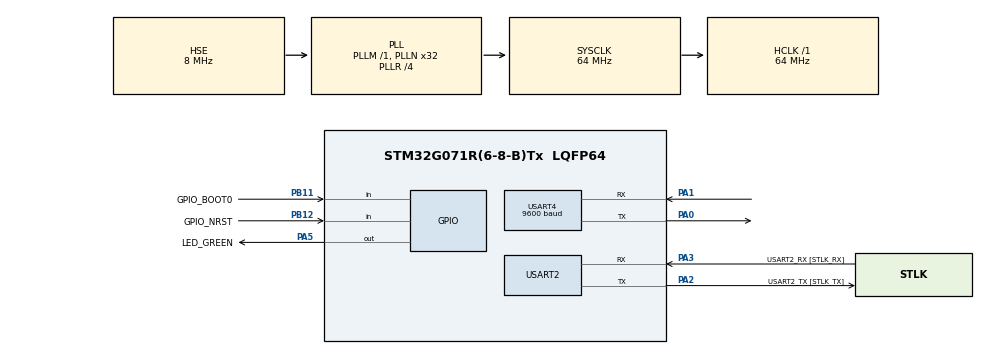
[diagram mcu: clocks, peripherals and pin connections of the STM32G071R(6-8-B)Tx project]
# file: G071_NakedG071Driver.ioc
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Dma.Request0=USART4_TX
Dma.Request1=USART4_RX
Dma.Request2=USART2_RX
Dma.Request3=USART2_TX
Dma.USART2_RX.2.Direction=DMA_PERIPH_TO_MEMORY
Dma.USART2_RX.2.EventEnable=DISABLE
Dma.USART2_RX.2.Instance=DMA1_Channel3
Dma.USART2_RX.2.MemDataAlignment=DMA_MDATAALIGN_BYTE
Dma.USART2_RX.2.MemInc=DMA_MINC_ENABLE
Dma.USART2_RX.2.Mode=DMA_NORMAL
Dma.USART2_RX.2.PeriphDataAlignment=DMA_PDATAALIGN_BYTE
Dma.USART2_RX.2.PeriphInc=DMA_PINC_DISABLE
Dma.USART2_RX.2.Polarity=HAL_DMAMUX_REQ_GEN_RISING
Dma.USART2_RX.2.Priority=DMA_PRIORITY_LOW
Dma.USART2_RX.2.RequestNumber=1
Dma.USART2_RX.2.SignalID=NONE
Dma.USART2_RX.2.SyncEnable=DISABLE
Dma.USART2_RX.2.SyncPolarity=HAL_DMAMUX_SYNC_NO_EVENT
Dma.USART2_RX.2.SyncRequestNumber=1
Dma.USART2_RX.2.SyncSignalID=NONE
Dma.USART2_TX.3.Direction=DMA_MEMORY_TO_PERIPH
Dma.USART2_TX.3.EventEnable=DISABLE
Dma.USART2_TX.3.Instance=DMA1_Channel4
Dma.USART2_TX.3.MemDataAlignment=DMA_MDATAALIGN_BYTE
Dma.USART2_TX.3.MemInc=DMA_MINC_ENABLE
Dma.USART2_TX.3.Mode=DMA_NORMAL
Dma.USART2_TX.3.PeriphDataAlignment=DMA_PDATAALIGN_BYTE
Dma.USART2_TX.3.PeriphInc=DMA_PINC_DISABLE
Dma.USART2_TX.3.Polarity=HAL_DMAMUX_REQ_GEN_RISING
Dma.USART2_TX.3.Priority=DMA_PRIORITY_LOW
Dma.USART2_TX.3.RequestNumber=1
Dma.USART2_TX.3.SignalID=NONE
Dma.USART2_TX.3.SyncEnable=DISABLE
Dma.USART2_TX.3.SyncPolarity=HAL_DMAMUX_SYNC_NO_EVENT
Dma.USART2_TX.3.SyncRequestNumber=1
Dma.USART2_TX.3.SyncSignalID=NONE
Dma.USART4_RX.1.Direction=DMA_PERIPH_TO_MEMORY
Dma.USART4_RX.1.EventEnable=DISABLE
Dma.USART4_RX.1.Instance=DMA1_Channel2
Dma.USART4_RX.1.MemDataAlignment=DMA_MDATAALIGN_BYTE
Dma.USART4_RX.1.MemInc=DMA_MINC_ENABLE
Dma.USART4_RX.1.Mode=DMA_NORMAL
Dma.USART4_RX.1.PeriphDataAlignment=DMA_PDATAALIGN_BYTE
Dma.USART4_RX.1.PeriphInc=DMA_PINC_DISABLE
Dma.USART4_RX.1.Polarity=HAL_DMAMUX_REQ_GEN_RISING
Dma.USART4_RX.1.Priority=DMA_PRIORITY_LOW
Dma.USART4_RX.1.RequestNumber=1
Dma.USART4_RX.1.SignalID=NONE
Dma.USART4_RX.1.SyncEnable=DISABLE
Dma.USART4_RX.1.SyncPolarity=HAL_DMAMUX_SYNC_NO_EVENT
Dma.USART4_RX.1.SyncRequestNumber=1
Dma.USART4_RX.1.SyncSignalID=NONE
Dma.USART4_TX.0.Direction=DMA_MEMORY_TO_PERIPH
Dma.USART4_TX.0.EventEnable=DISABLE
Dma.USART4_TX.0.Instance=DMA1_Channel1
Dma.USART4_TX.0.MemDataAlignment=DMA_MDATAALIGN_BYTE
Dma.USART4_TX.0.MemInc=DMA_MINC_ENABLE
Dma.USART4_TX.0.Mode=DMA_NORMAL
Dma.USART4_TX.0.PeriphDataAlignment=DMA_PDATAALIGN_BYTE
Dma.USART4_TX.0.PeriphInc=DMA_PINC_DISABLE
Dma.USART4_TX.0.Polarity=HAL_DMAMUX_REQ_GEN_RISING
Dma.USART4_TX.0.Priority=DMA_PRIORITY_LOW
Dma.USART4_TX.0.RequestNumber=1
Dma.USART4_TX.0.SignalID=NONE
Dma.USART4_TX.0.SyncEnable=DISABLE
Dma.USART4_TX.0.SyncPolarity=HAL_DMAMUX_SYNC_NO_EVENT
Dma.USART4_TX.0.SyncRequestNumber=1
Dma.USART4_TX.0.SyncSignalID=NONE
Mcu.Family=STM32G0
Mcu.Name=STM32G071R(6-8-B)Tx
Mcu.Package=LQFP64
NVIC.DMA1_Ch4_7_DMAMUX1_OVR_IRQn=true\:0\:0\:false\:false\:true\:false\:true
NVIC.DMA1_Channel1_IRQn=true\:0\:0\:false\:false\:true\:false\:true
NVIC.DMA1_Channel2_3_IRQn=true\:0\:0\:false\:false\:true\:false\:true
NVIC.USART2_IRQn=true\:0\:0\:false\:false\:true\:true\:true
NVIC.USART3_4_LPUART1_IRQn=true\:0\:0\:false\:false\:true\:true\:true
PA0.GPIO_PuPd=GPIO_NOPULL
PA0.GPIO_Speed=GPIO_SPEED_FREQ_HIGH
PA0.Mode=Asynchronous
PA0.Signal=USART4_TX
PA1.GPIO_PuPd=GPIO_NOPULL
PA1.GPIO_Speed=GPIO_SPEED_FREQ_HIGH
PA1.Mode=Asynchronous
PA1.Signal=USART4_RX
PA13.GPIO_Label=TMS
PA13.Mode=Serial_Wire
PA13.Signal=SYS_SWDIO
PA14-BOOT0.GPIO_Label=TCK
PA14-BOOT0.Mode=Serial_Wire
PA14-BOOT0.Signal=SYS_SWCLK
PA2.GPIO_Label=USART2_TX [STLK_TX]
PA2.GPIO_PuPd=GPIO_PULLUP
PA2.GPIO_Speed=GPIO_SPEED_FREQ_LOW
PA2.Mode=Asynchronous
PA2.Signal=USART2_TX
PA3.GPIO_Label=USART2_RX [STLK_RX]
PA3.GPIO_PuPd=GPIO_PULLUP
PA3.Mode=Asynchronous
PA3.Signal=USART2_RX
PA5.GPIO_Label=LED_GREEN
PA5.GPIO_Speed=GPIO_SPEED_FREQ_HIGH
PA5.Signal=GPIO_Output
PB11.GPIO_Label=GPIO_BOOT0
PB11.Signal=GPIO_Input
PB12.GPIO_Label=GPIO_NRST
PB12.Signal=GPIO_Input
PC13.Mode=SYS_WakeUp1
PC13.Signal=SYS_WKUP2
PC14-OSC32_IN\ (PC14).Mode=LSE-External-Oscillator
PC14-OSC32_IN\ (PC14).Signal=RCC_OSC32_IN
PC15-OSC32_OUT\ (PC15).Mode=LSE-External-Oscillator
PC15-OSC32_OUT\ (PC15).Signal=RCC_OSC32_OUT
PF0-OSC_IN\ (PF0).GPIO_Label=MCO
PF0-OSC_IN\ (PF0).Mode=HSE-External-Clock-Source
PF0-OSC_IN\ (PF0).Signal=RCC_OSC_IN
ProjectManager.HeapSize=0x200
ProjectManager.StackSize=0x400
ProjectManager.TargetToolchain=STM32CubeIDE
RCC.ADCFreq_Value=64000000
RCC.AHBFreq_Value=64000000
RCC.CortexFreq_Value=64000000
RCC.EXTERNAL_CLOCK_VALUE=12288000
RCC.HCLKFreq_Value=64000000
RCC.HSE_VALUE=8000000
RCC.HSI_VALUE=16000000
RCC.PLLN=32
RCC.PLLR=RCC_PLLR_DIV4
RCC.PLLSourceVirtual=RCC_PLLSOURCE_HSE
RCC.SYSCLKFreq_VALUE=64000000
RCC.SYSCLKSource=RCC_SYSCLKSOURCE_PLLCLK
RCC.VCOOutputFreq_Value=256000000
TIM14.Period=7
TIM14.Prescaler=0
TIM3.Period=65535
TIM3.Prescaler=63999
USART2.VirtualMode-Asynchronous=VM_ASYNC
USART4.BaudRate=9600
USART4.Parity=PARITY_EVEN
USART4.VirtualMode-Asynchronous=VM_ASYNC
USART4.WordLength=WORDLENGTH_9B
VP_SYS_VS_DBSignals.Mode=DisableDeadBatterySignals
VP_TIM14_VS_ClockSourceINT.Mode=Enable_Timer
VP_TIM3_VS_ClockSourceINT.Mode=Internal
board=NUCLEO-G071RB

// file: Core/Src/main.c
/* USER CODE BEGIN Header */
/**
  ******************************************************************************
  * @file           : main.c
  * @brief          : Main program body
  ******************************************************************************
  * @attention
  *
  * <h2><center>&copy; Copyright (c) 2020 STMicroelectronics.
  * All rights reserved.</center></h2>
  *
  * This software component is licensed by ST under BSD 3-Clause license,
  * the "License"; You may not use this file except in compliance with the
  * License. You may obtain a copy of the License at:
  *                        opensource.org/licenses/BSD-3-Clause
  *
  ******************************************************************************
  */
/* USER CODE END Header */
#include "main.h"

TIM_HandleTypeDef htim3;
TIM_HandleTypeDef htim14;

UART_HandleTypeDef huart2;
UART_HandleTypeDef huart4;
DMA_HandleTypeDef hdma_usart2_rx;
DMA_HandleTypeDef hdma_usart2_tx;
DMA_HandleTypeDef hdma_usart4_tx;
DMA_HandleTypeDef hdma_usart4_rx;

/* USER CODE BEGIN PV */
uint8_t pc_rx_buff[10];
uint8_t pc_tx_buff[256];

/* USER CODE END PV */

void SystemClock_Config(void);
static void MX_GPIO_Init(void);
static void MX_DMA_Init(void);
static void MX_USART2_UART_Init(void);
static void MX_TIM14_Init(void);
static void MX_USART4_UART_Init(void);
static void MX_TIM3_Init(void);

int main(void)
{

  /* MCU Configuration--------------------------------------------------------*/

  /* Reset of all peripherals, Initializes the Flash interface and the Systick. */
  HAL_Init();

  /* Configure the system clock */
  SystemClock_Config();

  /* USER CODE BEGIN SysInit */
#if 0
  MX_GPIO_Init();
  MX_USART2_UART_Init();
  MX_TIM14_Init();
  MX_USART4_UART_Init();
  MX_DMA_Init();
#endif

#if 1
  /* USER CODE END SysInit */

  /* Initialize all configured peripherals */
  MX_GPIO_Init();
  MX_DMA_Init();
  MX_USART2_UART_Init();
  MX_TIM14_Init();
  MX_USART4_UART_Init();
  MX_TIM3_Init();
  /* USER CODE BEGIN 2 */
#endif

	HAL_UART_Receive_DMA(&huart2, pc_rx_buff, 1);

	//HAL_TIM_PWM_Start(&htim14, TIM_CHANNEL_1);

  /* USER CODE END 2 */

  /* Infinite loop */
  /* USER CODE BEGIN WHILE */
  while (1)
  {
	 // HAL_UART_Transmit_DMA(&huart2, pc_tx_buff, len);
	 // HAL_Delay(10);
    /* USER CODE END WHILE */

  }
}

void SystemClock_Config(void)
{
  RCC_OscInitTypeDef RCC_OscInitStruct = {0};
  RCC_ClkInitTypeDef RCC_ClkInitStruct = {0};
  RCC_PeriphCLKInitTypeDef PeriphClkInit = {0};

  /** Configure the main internal regulator output voltage
  */
  HAL_PWREx_ControlVoltageScaling(PWR_REGULATOR_VOLTAGE_SCALE1);
  /** Initializes the RCC Oscillators according to the specified parameters
  * in the RCC_OscInitTypeDef structure.
  */
  RCC_OscInitStruct.OscillatorType = RCC_OSCILLATORTYPE_HSE;
  RCC_OscInitStruct.HSEState = RCC_HSE_BYPASS;
  RCC_OscInitStruct.PLL.PLLState = RCC_PLL_ON;
  RCC_OscInitStruct.PLL.PLLSource = RCC_PLLSOURCE_HSE;
  RCC_OscInitStruct.PLL.PLLM = RCC_PLLM_DIV1;
  RCC_OscInitStruct.PLL.PLLN = 32;
  RCC_OscInitStruct.PLL.PLLP = RCC_PLLP_DIV2;
  RCC_OscInitStruct.PLL.PLLQ = RCC_PLLQ_DIV2;
  RCC_OscInitStruct.PLL.PLLR = RCC_PLLR_DIV4;
  if (HAL_RCC_OscConfig(&RCC_OscInitStruct) != HAL_OK)
  {
    Error_Handler();
  }
  /** Initializes the CPU, AHB and APB buses clocks
  */
  RCC_ClkInitStruct.ClockType = RCC_CLOCKTYPE_HCLK|RCC_CLOCKTYPE_SYSCLK
                              |RCC_CLOCKTYPE_PCLK1;
  RCC_ClkInitStruct.SYSCLKSource = RCC_SYSCLKSOURCE_PLLCLK;
  RCC_ClkInitStruct.AHBCLKDivider = RCC_SYSCLK_DIV1;
  RCC_ClkInitStruct.APB1CLKDivider = RCC_HCLK_DIV1;

  if (HAL_RCC_ClockConfig(&RCC_ClkInitStruct, FLASH_LATENCY_2) != HAL_OK)
  {
    Error_Handler();
  }
  /** Initializes the peripherals clocks
  */
  PeriphClkInit.PeriphClockSelection = RCC_PERIPHCLK_USART2;
  PeriphClkInit.Usart2ClockSelection = RCC_USART2CLKSOURCE_PCLK1;
  if (HAL_RCCEx_PeriphCLKConfig(&PeriphClkInit) != HAL_OK)
  {
    Error_Handler();
  }
}

static void MX_TIM3_Init(void)
{

  TIM_ClockConfigTypeDef sClockSourceConfig = {0};
  TIM_MasterConfigTypeDef sMasterConfig = {0};

  htim3.Instance = TIM3;
  htim3.Init.Prescaler = 63999;
  htim3.Init.CounterMode = TIM_COUNTERMODE_UP;
  htim3.Init.Period = 65535;
  htim3.Init.ClockDivision = TIM_CLOCKDIVISION_DIV1;
  htim3.Init.AutoReloadPreload = TIM_AUTORELOAD_PRELOAD_DISABLE;
  if (HAL_TIM_Base_Init(&htim3) != HAL_OK)
  {
    Error_Handler();
  }
  sClockSourceConfig.ClockSource = TIM_CLOCKSOURCE_INTERNAL;
  if (HAL_TIM_ConfigClockSource(&htim3, &sClockSourceConfig) != HAL_OK)
  {
    Error_Handler();
  }
  sMasterConfig.MasterOutputTrigger = TIM_TRGO_RESET;
  sMasterConfig.MasterSlaveMode = TIM_MASTERSLAVEMODE_DISABLE;
  if (HAL_TIMEx_MasterConfigSynchronization(&htim3, &sMasterConfig) != HAL_OK)
  {
    Error_Handler();
  }

}

static void MX_TIM14_Init(void)
{

  htim14.Instance = TIM14;
  htim14.Init.Prescaler = 0;
  htim14.Init.CounterMode = TIM_COUNTERMODE_UP;
  htim14.Init.Period = 7;
  htim14.Init.ClockDivision = TIM_CLOCKDIVISION_DIV1;
  htim14.Init.AutoReloadPreload = TIM_AUTORELOAD_PRELOAD_DISABLE;
  if (HAL_TIM_Base_Init(&htim14) != HAL_OK)
  {
    Error_Handler();
  }

}

static void MX_USART2_UART_Init(void)
{

  huart2.Instance = USART2;
  huart2.Init.BaudRate = 115200;
  huart2.Init.WordLength = UART_WORDLENGTH_8B;
  huart2.Init.StopBits = UART_STOPBITS_1;
  huart2.Init.Parity = UART_PARITY_NONE;
  huart2.Init.Mode = UART_MODE_TX_RX;
  huart2.Init.HwFlowCtl = UART_HWCONTROL_NONE;
  huart2.Init.OverSampling = UART_OVERSAMPLING_16;
  huart2.Init.OneBitSampling = UART_ONE_BIT_SAMPLE_DISABLE;
  huart2.Init.ClockPrescaler = UART_PRESCALER_DIV1;
  huart2.AdvancedInit.AdvFeatureInit = UART_ADVFEATURE_NO_INIT;
  if (HAL_UART_Init(&huart2) != HAL_OK)
  {
    Error_Handler();
  }
  if (HAL_UARTEx_SetTxFifoThreshold(&huart2, UART_TXFIFO_THRESHOLD_1_8) != HAL_OK)
  {
    Error_Handler();
  }
  if (HAL_UARTEx_SetRxFifoThreshold(&huart2, UART_RXFIFO_THRESHOLD_1_8) != HAL_OK)
  {
    Error_Handler();
  }
  if (HAL_UARTEx_DisableFifoMode(&huart2) != HAL_OK)
  {
    Error_Handler();
  }

}

static void MX_USART4_UART_Init(void)
{

  huart4.Instance = USART4;
  huart4.Init.BaudRate = 9600;
  huart4.Init.WordLength = UART_WORDLENGTH_9B;
  huart4.Init.StopBits = UART_STOPBITS_1;
  huart4.Init.Parity = UART_PARITY_EVEN;
  huart4.Init.Mode = UART_MODE_TX_RX;
  huart4.Init.HwFlowCtl = UART_HWCONTROL_NONE;
  huart4.Init.OverSampling = UART_OVERSAMPLING_16;
  huart4.Init.OneBitSampling = UART_ONE_BIT_SAMPLE_DISABLE;
  huart4.Init.ClockPrescaler = UART_PRESCALER_DIV1;
  huart4.AdvancedInit.AdvFeatureInit = UART_ADVFEATURE_NO_INIT;
  if (HAL_UART_Init(&huart4) != HAL_OK)
  {
    Error_Handler();
  }

}

static void MX_DMA_Init(void)
{

  /* DMA controller clock enable */
  __HAL_RCC_DMA1_CLK_ENABLE();

  /* DMA interrupt init */
  /* DMA1_Channel1_IRQn interrupt configuration */
  HAL_NVIC_SetPriority(DMA1_Channel1_IRQn, 0, 0);
  HAL_NVIC_EnableIRQ(DMA1_Channel1_IRQn);
  /* DMA1_Channel2_3_IRQn interrupt configuration */
  HAL_NVIC_SetPriority(DMA1_Channel2_3_IRQn, 0, 0);
  HAL_NVIC_EnableIRQ(DMA1_Channel2_3_IRQn);
  /* DMA1_Ch4_7_DMAMUX1_OVR_IRQn interrupt configuration */
  HAL_NVIC_SetPriority(DMA1_Ch4_7_DMAMUX1_OVR_IRQn, 0, 0);
  HAL_NVIC_EnableIRQ(DMA1_Ch4_7_DMAMUX1_OVR_IRQn);

}

static void MX_GPIO_Init(void)
{
  GPIO_InitTypeDef GPIO_InitStruct = {0};

  /* GPIO Ports Clock Enable */
  __HAL_RCC_GPIOC_CLK_ENABLE();
  __HAL_RCC_GPIOF_CLK_ENABLE();
  __HAL_RCC_GPIOA_CLK_ENABLE();
  __HAL_RCC_GPIOB_CLK_ENABLE();

  /*Configure GPIO pin Output Level */
  HAL_GPIO_WritePin(LED_GREEN_GPIO_Port, LED_GREEN_Pin, GPIO_PIN_RESET);

  /*Configure GPIO pin : LED_GREEN_Pin */
  GPIO_InitStruct.Pin = LED_GREEN_Pin;
  GPIO_InitStruct.Mode = GPIO_MODE_OUTPUT_PP;
  GPIO_InitStruct.Pull = GPIO_NOPULL;
  GPIO_InitStruct.Speed = GPIO_SPEED_FREQ_HIGH;
  HAL_GPIO_Init(LED_GREEN_GPIO_Port, &GPIO_InitStruct);

  /*Configure GPIO pins : GPIO_BOOT0_Pin GPIO_NRST_Pin */
  GPIO_InitStruct.Pin = GPIO_BOOT0_Pin|GPIO_NRST_Pin;
  GPIO_InitStruct.Mode = GPIO_MODE_INPUT;
  GPIO_InitStruct.Pull = GPIO_NOPULL;
  HAL_GPIO_Init(GPIOB, &GPIO_InitStruct);

}

void Error_Handler(void)
{
}

/************************ (C) COPYRIGHT STMicroelectronics *****END OF FILE****/
